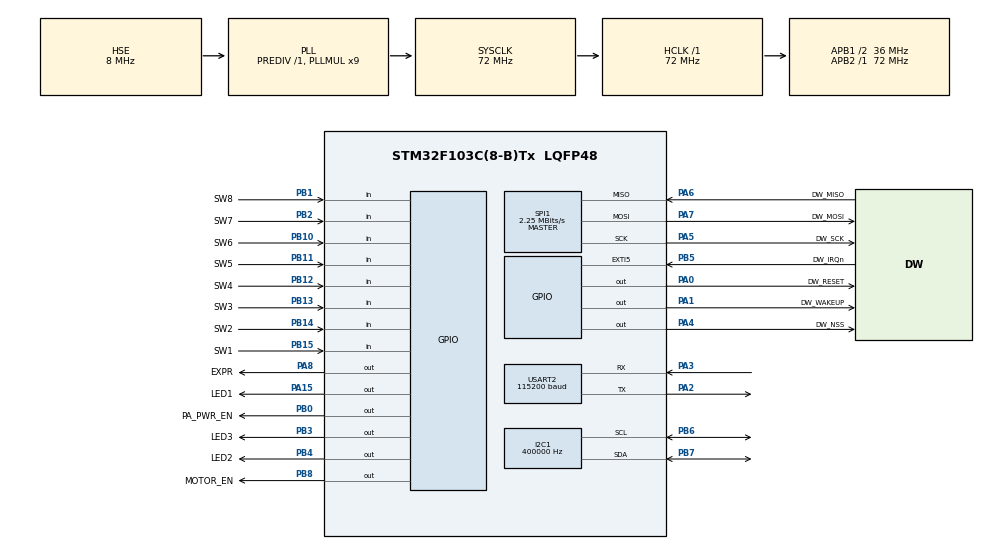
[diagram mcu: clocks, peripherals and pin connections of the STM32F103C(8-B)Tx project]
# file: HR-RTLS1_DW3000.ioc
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Dma.Request0=USART2_RX
Dma.Request1=USART2_TX
Dma.USART2_RX.0.Direction=DMA_PERIPH_TO_MEMORY
Dma.USART2_RX.0.Instance=DMA1_Channel6
Dma.USART2_RX.0.MemDataAlignment=DMA_MDATAALIGN_BYTE
Dma.USART2_RX.0.MemInc=DMA_MINC_ENABLE
Dma.USART2_RX.0.Mode=DMA_CIRCULAR
Dma.USART2_RX.0.PeriphDataAlignment=DMA_PDATAALIGN_BYTE
Dma.USART2_RX.0.PeriphInc=DMA_PINC_DISABLE
Dma.USART2_RX.0.Priority=DMA_PRIORITY_LOW
Dma.USART2_TX.1.Direction=DMA_MEMORY_TO_PERIPH
Dma.USART2_TX.1.Instance=DMA1_Channel7
Dma.USART2_TX.1.MemDataAlignment=DMA_MDATAALIGN_BYTE
Dma.USART2_TX.1.MemInc=DMA_MINC_ENABLE
Dma.USART2_TX.1.Mode=DMA_NORMAL
Dma.USART2_TX.1.PeriphDataAlignment=DMA_PDATAALIGN_BYTE
Dma.USART2_TX.1.PeriphInc=DMA_PINC_DISABLE
Dma.USART2_TX.1.Priority=DMA_PRIORITY_HIGH
I2C1.AddressingMode=I2C_ADDRESSINGMODE_7BIT
I2C1.ClockSpeed=400000
I2C1.DualAddressMode=I2C_DUALADDRESS_DISABLE
I2C1.DutyCycle=I2C_DUTYCYCLE_2
I2C1.GeneralCallMode=I2C_GENERALCALL_DISABLE
I2C1.I2C_Mode=I2C_Fast
I2C1.NoStretchMode=I2C_NOSTRETCH_DISABLE
I2C1.OwnAddress=0
IWDG.Prescaler=IWDG_PRESCALER_64
IWDG.Reload=1000
Mcu.Family=STM32F1
Mcu.Name=STM32F103C(8-B)Tx
Mcu.Package=LQFP48
NVIC.DMA1_Channel6_IRQn=true\:0\:0\:false\:false\:true\:false\:true
NVIC.DMA1_Channel7_IRQn=true\:0\:0\:false\:false\:true\:false\:true
NVIC.EXTI9_5_IRQn=true\:0\:0\:true\:false\:true\:true\:true
NVIC.PriorityGroup=NVIC_PRIORITYGROUP_4
NVIC.USART2_IRQn=true\:1\:0\:true\:false\:true\:true\:true
PA0-WKUP.GPIO_Label=DW_RESET
PA0-WKUP.GPIO_ModeDefaultOutputPP=GPIO_MODE_OUTPUT_OD
PA0-WKUP.Signal=GPIO_Output
PA1.GPIO_Label=DW_WAKEUP
PA1.GPIO_Speed=GPIO_SPEED_FREQ_MEDIUM
PA1.Signal=GPIO_Output
PA13.GPIO_Label=J_TMS
PA13.Mode=Serial_Wire
PA13.Signal=SYS_JTMS-SWDIO
PA14.GPIO_Label=J_TCK
PA14.Mode=Serial_Wire
PA14.Signal=SYS_JTCK-SWCLK
PA15.GPIO_Label=LED1
PA15.GPIO_Speed=GPIO_SPEED_FREQ_LOW
PA15.PinState=GPIO_PIN_SET
PA15.Signal=GPIO_Output
PA2.Mode=Asynchronous
PA2.Signal=USART2_TX
PA3.Mode=Asynchronous
PA3.Signal=USART2_RX
PA4.GPIO_Label=DW_NSS
PA4.GPIO_Speed=GPIO_SPEED_FREQ_HIGH
PA4.PinState=GPIO_PIN_SET
PA4.Signal=GPIO_Output
PA5.GPIO_Label=DW_SCK
PA5.Mode=Full_Duplex_Master
PA5.Signal=SPI1_SCK
PA6.GPIO_Label=DW_MISO
PA6.GPIO_PuPd=GPIO_PULLUP
PA6.Mode=Full_Duplex_Master
PA6.Signal=SPI1_MISO
PA7.GPIO_Label=DW_MOSI
PA7.Mode=Full_Duplex_Master
PA7.Signal=SPI1_MOSI
PA8.GPIO_Label=EXPR
PA8.GPIO_PuPd=GPIO_PULLDOWN
PA8.GPIO_Speed=GPIO_SPEED_FREQ_LOW
PA8.Signal=GPIO_Output
PB0.GPIO_Label=PA_PWR_EN
PB0.GPIO_PuPd=GPIO_PULLUP
PB0.Signal=GPIO_Output
PB1.GPIO_Label=SW8
PB1.GPIO_PuPd=GPIO_PULLUP
PB1.Signal=GPIO_Input
PB10.GPIO_Label=SW6
PB10.GPIO_PuPd=GPIO_PULLUP
PB10.Signal=GPIO_Input
PB11.GPIO_Label=SW5
PB11.GPIO_PuPd=GPIO_PULLUP
PB11.Signal=GPIO_Input
PB12.GPIO_Label=SW4
PB12.GPIO_PuPd=GPIO_PULLUP
PB12.Signal=GPIO_Input
PB13.GPIO_Label=SW3
PB13.GPIO_PuPd=GPIO_PULLUP
PB13.Signal=GPIO_Input
PB14.GPIO_Label=SW2
PB14.GPIO_PuPd=GPIO_PULLUP
PB14.Signal=GPIO_Input
PB15.GPIO_Label=SW1
PB15.GPIO_PuPd=GPIO_PULLUP
PB15.Signal=GPIO_Input
PB2.GPIO_Label=SW7
PB2.GPIO_PuPd=GPIO_PULLUP
PB2.Signal=GPIO_Input
PB3.GPIO_Label=LED3
PB3.PinState=GPIO_PIN_SET
PB3.Signal=GPIO_Output
PB4.GPIO_Label=LED2
PB4.GPIO_ModeDefaultOutputPP=GPIO_MODE_OUTPUT_PP
PB4.GPIO_Speed=GPIO_SPEED_FREQ_LOW
PB4.PinState=GPIO_PIN_SET
PB4.Signal=GPIO_Output
PB5.GPIO_Label=DW_IRQn
PB5.GPIO_ModeDefaultEXTI=GPIO_MODE_IT_RISING
PB5.GPIO_PuPd=GPIO_PULLDOWN
PB5.Signal=GPXTI5
PB6.Mode=I2C
PB6.Signal=I2C1_SCL
PB7.Mode=I2C
PB7.Signal=I2C1_SDA
PB8.GPIO_Label=MOTOR_EN
PB8.GPIO_PuPd=GPIO_PULLDOWN
PB8.Signal=GPIO_Output
PD0-OSC_IN.Mode=HSE-External-Oscillator
PD0-OSC_IN.Signal=RCC_OSC_IN
PD1-OSC_OUT.Mode=HSE-External-Oscillator
PD1-OSC_OUT.Signal=RCC_OSC_OUT
ProjectManager.HeapSize=0x200
ProjectManager.StackSize=0x1000
ProjectManager.TargetToolchain=MDK-ARM V5
RCC.AHBFreq_Value=72000000
RCC.APB1CLKDivider=RCC_HCLK_DIV2
RCC.APB1Freq_Value=36000000
RCC.APB1TimFreq_Value=72000000
RCC.APB2Freq_Value=72000000
RCC.APB2TimFreq_Value=72000000
RCC.HCLKFreq_Value=72000000
RCC.PLLMUL=RCC_PLL_MUL9
RCC.PLLSourceVirtual=RCC_PLLSOURCE_HSE
RCC.SYSCLKFreq_VALUE=72000000
RCC.SYSCLKSource=RCC_SYSCLKSOURCE_PLLCLK
RCC.USBFreq_Value=72000000
SPI1.BaudRatePrescaler=SPI_BAUDRATEPRESCALER_32
SPI1.CLKPhase=SPI_PHASE_1EDGE
SPI1.CLKPolarity=SPI_POLARITY_LOW
SPI1.CRCCalculation=SPI_CRCCALCULATION_DISABLE
SPI1.CalculateBaudRate=2.25 MBits/s
SPI1.DataSize=SPI_DATASIZE_8BIT
SPI1.Direction=SPI_DIRECTION_2LINES
SPI1.FirstBit=SPI_FIRSTBIT_MSB
SPI1.Mode=SPI_MODE_MASTER
SPI1.NSS=SPI_NSS_SOFT
SPI1.TIMode=SPI_TIMODE_DISABLE
SPI1.VirtualType=VM_MASTER
USART2.BaudRate=115200
USART2.Mode=MODE_TX_RX
USART2.OverSampling=UART_OVERSAMPLING_16
USART2.Parity=PARITY_NONE
USART2.StopBits=STOPBITS_1
USART2.VirtualMode=VM_ASYNC
USART2.WordLength=WORDLENGTH_8B
VP_IWDG_VS_IWDG.Mode=IWDG_Activate
board=TREK1000_CubeMx

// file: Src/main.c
/* USER CODE BEGIN Header */
/**
  ******************************************************************************
  * @file           : main.c
  * @brief          : Main program body
  ******************************************************************************
  */
/* USER CODE END Header */
#include "main.h"
#include "dma.h"
#include "i2c.h"
#include "iwdg.h"
#include "spi.h"
#include "usart.h"
#include "gpio.h"

/* USER CODE BEGIN Includes */
#include "instance.h"
/* USER CODE END Includes */

/* USER CODE BEGIN PTD */
extern uint8_t UART_RX_BUF[200];
/* USER CODE END PTD */

/* USER CODE BEGIN PV */
extern void dw_main(void);
/* USER CODE END PV */

void SystemClock_Config(void);

int main(void)
{

  /* MCU Configuration--------------------------------------------------------*/

  /* Reset of all peripherals, Initializes the Flash interface and the Systick. */
  HAL_Init();

  /* Configure the system clock */
  SystemClock_Config();

  /* Initialize all configured peripherals */
  MX_GPIO_Init();
  MX_DMA_Init();
  MX_SPI1_Init();
  MX_USART2_UART_Init();
  MX_I2C1_Init();
  // MX_IWDG_Init();
  /* USER CODE BEGIN 2 */
	USE_OLED = SSD1306_Init();
#if defined(USE_IMU_IC)
	USE_IMU = Icm42605Init();
#endif

  // USE_EXT_EEPROM = e2prom_Init();

  __HAL_UART_ENABLE_IT(&huart2, UART_IT_IDLE);
  HAL_UART_Receive_DMA(&huart2, &UART_RX_BUF[0], sizeof(UART_RX_BUF));

  port_DisableEXT_IRQ();
  setup_DWICRSTnIRQ(0);
	// MX_IWDG_Init();
  dw_main();
  /* USER CODE END 2 */

  /* Infinite loop */
  while (1)
  {

  }
}

void SystemClock_Config(void)
{
  RCC_OscInitTypeDef RCC_OscInitStruct = {0};
  RCC_ClkInitTypeDef RCC_ClkInitStruct = {0};

  /** Initializes the RCC Oscillators according to the specified parameters
  * in the RCC_OscInitTypeDef structure.
  */
  RCC_OscInitStruct.OscillatorType = RCC_OSCILLATORTYPE_LSI|RCC_OSCILLATORTYPE_HSE;
  RCC_OscInitStruct.HSEState = RCC_HSE_ON;
  RCC_OscInitStruct.HSEPredivValue = RCC_HSE_PREDIV_DIV1;
  RCC_OscInitStruct.HSIState = RCC_HSI_ON;
  RCC_OscInitStruct.LSIState = RCC_LSI_ON;
  RCC_OscInitStruct.PLL.PLLState = RCC_PLL_ON;
  RCC_OscInitStruct.PLL.PLLSource = RCC_PLLSOURCE_HSE;
  RCC_OscInitStruct.PLL.PLLMUL = RCC_PLL_MUL9;
  if (HAL_RCC_OscConfig(&RCC_OscInitStruct) != HAL_OK)
  {
    Error_Handler();
  }
  /** Initializes the CPU, AHB and APB buses clocks
  */
  RCC_ClkInitStruct.ClockType = RCC_CLOCKTYPE_HCLK|RCC_CLOCKTYPE_SYSCLK
                              |RCC_CLOCKTYPE_PCLK1|RCC_CLOCKTYPE_PCLK2;
  RCC_ClkInitStruct.SYSCLKSource = RCC_SYSCLKSOURCE_PLLCLK;
  RCC_ClkInitStruct.AHBCLKDivider = RCC_SYSCLK_DIV1;
  RCC_ClkInitStruct.APB1CLKDivider = RCC_HCLK_DIV2;
  RCC_ClkInitStruct.APB2CLKDivider = RCC_HCLK_DIV1;

  if (HAL_RCC_ClockConfig(&RCC_ClkInitStruct, FLASH_LATENCY_2) != HAL_OK)
  {
    Error_Handler();
  }
}

void Error_Handler(void)
{
}

/************************ (C) COPYRIGHT STMicroelectronics *****END OF FILE****/
